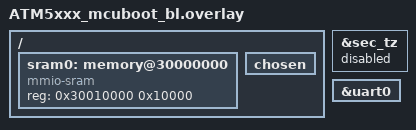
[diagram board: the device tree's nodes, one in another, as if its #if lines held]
/*
 * Copyright (c) 2025-2026 Atmosic
 *
 * SPDX-License-Identifier: LicenseRef-Atmosic
 */

#include <arm/atmosic/ATM5xxx_mcuboot_partitions.dtsi>

/ {
	sram0: memory@30000000 {
		device_type = "memory";
		compatible = "mmio-sram";
		reg = <0x30010000 0x10000>;
	};

	chosen {
		/delete-property/ zephyr,entropy;
	};
};

/* secure board file used, but TZ is not actually used */
&sec_tz {
	status = "disabled";
	/delete-property/ allow_nsc_in_ram;
};

#ifdef USE_ATM_SECURE_DEBUG
&uart0 {
       status = "okay";
};
#endif
